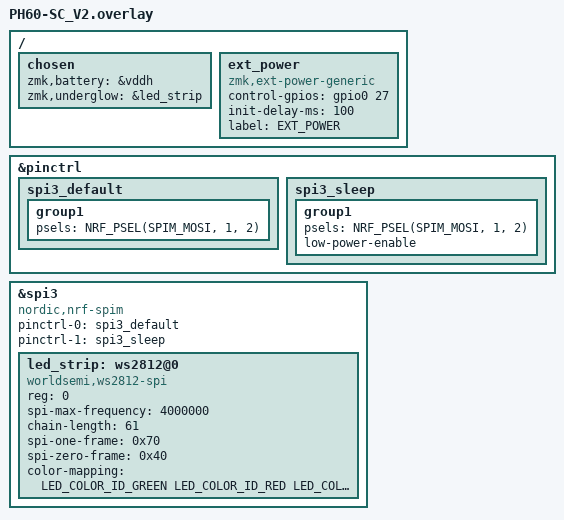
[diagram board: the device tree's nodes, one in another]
/*
 * Copyright (c) 2025 Team PHDesign
 *
 * SPDX-License-Identifier: MIT
 */

#include "PH60-SC_V2.dtsi"
#include <dt-bindings/led/led.h>

&pinctrl {
	spi3_default: spi3_default {
		group1 {
			psels = <NRF_PSEL(SPIM_MOSI, 1, 2)>;
		};
	};

	spi3_sleep: spi3_sleep {
		group1 {
			psels = <NRF_PSEL(SPIM_MOSI, 1, 2)>;
			low-power-enable;
		};
	};
};

&spi3 {
	compatible = "nordic,nrf-spim";
	status = "okay";

	pinctrl-0 = <&spi3_default>;
	pinctrl-1 = <&spi3_sleep>;
	pinctrl-names = "default", "sleep";

	led_strip: ws2812@0 {
		compatible = "worldsemi,ws2812-spi";

		/* SPI */
		reg = <0>; /* ignored, but necessary for SPI bindings */
		spi-max-frequency = <4000000>;

		/* WS2812 */
		chain-length = <61>; /* 61 keys, each with one RGB LED */
		spi-one-frame = <0x70>;
		spi-zero-frame = <0x40>;
		color-mapping = <LED_COLOR_ID_GREEN
				 LED_COLOR_ID_RED
				 LED_COLOR_ID_BLUE>;
	};
};

/ {
	chosen {
		zmk,battery = &vddh;
		zmk,underglow = &led_strip;
	};

    ext_power: ext_power {
        compatible = "zmk,ext-power-generic";
        control-gpios = <&gpio0 27 GPIO_ACTIVE_HIGH>;
        init-delay-ms = <50>;
    };
	ext_power {
		compatible = "zmk,ext-power-generic";
		label = "EXT_POWER";
		control-gpios = <&gpio0 27 GPIO_ACTIVE_HIGH>;
		init-delay-ms = <100>;
	};
};


